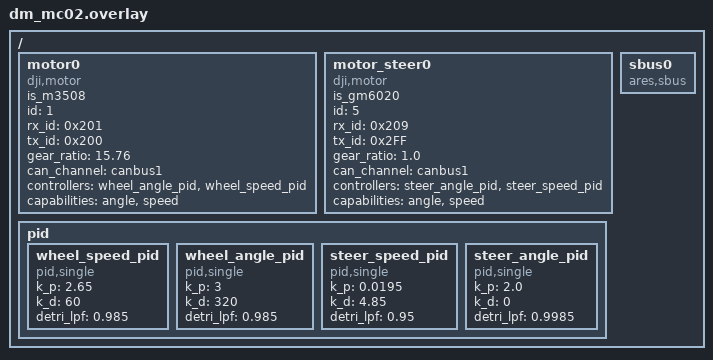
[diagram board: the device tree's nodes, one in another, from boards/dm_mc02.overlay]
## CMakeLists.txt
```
# SPDX-License-Identifier: Apache-2.0

cmake_minimum_required(VERSION 3.20.0)
set(CMAKE_CXX_STANDARD 11)
find_package(Zephyr REQUIRED HINTS $ENV{ZEPHYR_BASE})
project(motor)

FILE(GLOB app_sources src/*.c)

include_directories(${ZEPHYR_BASE}/include)
include_directories(${CMAKE_CURRENT_SOURCE_DIR}/include)
include_directories(${CMAKE_CURRENT_SOURCE_DIR}/dts)
target_sources(app PRIVATE ${app_sources})
target_include_directories(app PRIVATE ${ZEPHYR_BASE}/include)
target_include_directories(app PRIVATE ${CMAKE_CURRENT_SOURCE_DIR}/include)
target_include_directories(app PRIVATE ${CMAKE_CURRENT_SOURCE_DIR}/dts)
```

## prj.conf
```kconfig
# 启用线程分析器
CONFIG_THREAD_ANALYZER=y
CONFIG_THREAD_ANALYZER_USE_LOG=y
CONFIG_THREAD_ANALYZER_USE_PRINTK=n
CONFIG_THREAD_NAME=y
# CONFIG_THREAD_ANALYZER_AUTO=y
# CONFIG_THREAD_ANALYZER_AUTO_INTERVAL=5
CONFIG_THREAD_ANALYZER_LOG_LEVEL_INF=y
CONFIG_THREAD_ANALYZER_AUTO_SEPARATE_CORES=n

# 启用 Shell 支持
CONFIG_SHELL=n
CONFIG_SHELL_BACKENDS=n
CONFIG_SHELL_BACKEND_SERIAL=n

# 启用 UART 控制台
CONFIG_UART_CONSOLE=y

# 禁用 SEGGER RTT
CONFIG_USE_SEGGER_RTT=n

# 启用事件支持
CONFIG_EVENTS=y

# 启用控制台支持
CONFIG_CONSOLE=y

# 启用日志系统
CONFIG_LOG=y
CONFIG_LOG_MODE_IMMEDIATE=y
CONFIG_LOG_PRINTK=y
CONFIG_LOG_BACKEND_UART=y
# CONFIG_LOG_MODE_IMMEDIATE=y

# 启用串行支持
CONFIG_SERIAL=y

# 禁用优化
CONFIG_NO_OPTIMIZATIONS=n
CONFIG_COMPILER_OPT=""

# 启用驱动
CONFIG_MOTOR=y
CONFIG_MOTOR_DJI=y
CONFIG_MOTOR_LOG_LEVEL=4
CONFIG_CAN=y
CONFIG_MOTOR_INIT_PRIORITY=90

CONFIG_ARES=y

# use ASYNC uart API
CONFIG_SERIAL=y
CONFIG_UART_ASYNC_API=y
CONFIG_UART_INTERRUPT_DRIVEN=y

CONFIG_DMA=y
CONFIG_DMA_STM32=y  # STM32 DMA 驱动
CONFIG_UART_STM32=y # STM32 UART 驱动
# CONFIG_STM32_UART_DMA=y

# CONFIG_HAS_STM32CUBE=y
# CONFIG_USE_STM32_HAL_DMA=y
CONFIG_SPI=y
CONFIG_SPI_STM32=y

CONFIG_DEBUG=y

CONFIG_CMSIS_DSP=y
CONFIG_CMSIS_DSP_MATRIX=y
CONFIG_CMSIS_DSP_CONTROLLER=y
CONFIG_CMSIS_DSP_FASTMATH=y
```

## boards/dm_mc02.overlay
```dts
/ {
	motor0: motor0{
		compatible = "dji,motor";
		is_m3508;
		id = <1>;
		rx_id = <0x201>;
		tx_id = <0x200>;
		gear_ratio = "15.76";
		status = "okay";
		can_channel = <&canbus1>;
		controllers = <&wheel_angle_pid &wheel_speed_pid>;
		capabilities = "angle", "speed";
	};
	motor_steer0: motor_steer0{
		compatible = "dji,motor";
		is_gm6020;
		id = <5>;
		rx_id = <0x209>;
		tx_id = <0x2FF>;
		gear_ratio = "1.0";
		status = "okay";
		can_channel = <&canbus1>;
		controllers = <&steer_angle_pid &steer_speed_pid>;
		capabilities = "angle", "speed";
	};

	pid {
		wheel_speed_pid: wheel_speed_pid {
			#controller-cells = <0>;
			compatible = "pid,single";
			k_p = "2.65";
			k_d = "60";
			detri_lpf = "0.985";
		};

		wheel_angle_pid: wheel_angle_pid {
			#controller-cells = <0>;
			compatible = "pid,single";
			k_p = "3";
			k_d = "320";
			detri_lpf = "0.985";
		};

		steer_speed_pid: steer_speed_pid {
			#controller-cells = <0>;
			compatible = "pid,single";
			k_p = "0.0195";
			k_d = "4.85";
			detri_lpf = "0.95";
		};

		steer_angle_pid: steer_angle_pid {
			#controller-cells = <0>;
			compatible = "pid,single";
			k_p = "2.0";
			k_d = "0";
			detri_lpf = "0.9985";
		};
	};
	sbus0: sbus0 {
		compatible = "ares,sbus";
		status = "okay";
	};
};
```

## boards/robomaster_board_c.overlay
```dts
/ {
	motor0: motor0{
		compatible = "dji,motor";
		is_m3508;
		id = <1>;
		rx_id = <0x201>;
		tx_id = <0x200>;
		gear_ratio = "19.20";
		status = "okay";
		can_channel = <&canbus1>;
		controllers = <&speed_pid>;
		capabilities = "speed";
	};

	pid {
		speed_pid: speed_pid {
			#controller-cells = <0>;
			compatible = "pid,single";
			k_p = "1.8";
			k_i = "2.0";
			k_d = "2";
			detri_lpf = "0.985";
		};
	};
	sbus0: sbus0 {
		compatible = "ares,sbus";
		status = "okay";
	};
};
```

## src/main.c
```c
/*
 * Copyright (c) 2024 ttwards <12411711@mail.sustech.edu.cn>
 *
 * SPDX-License-Identifier: Apache-2.0
 */

#include <stddef.h>
#include <stdint.h>
#include <zephyr/device.h>
#include <zephyr/logging/log.h>
#include <zephyr/devicetree.h>
#include <zephyr/drivers/can.h>
#include <zephyr/debug/thread_analyzer.h>
#include <zephyr/kernel.h>
#include <zephyr/sys/printk.h>
#include <zephyr/drivers/motor.h>
#include <ares/board/init.h>

LOG_MODULE_REGISTER(main, LOG_LEVEL_DBG);

#define HIGH_BYTE(x)           ((x) >> 8)
#define LOW_BYTE(x)            ((x) & 0xFF)
#define COMBINE_HL8(HIGH, LOW) ((HIGH << 8) + LOW)

/* Devicetree */
#define CANBUS_NODE DT_CHOSEN(zephyr_canbus)
#define CAN1_NODE   DT_INST(0, vnd_canbus)
#define MOTOR1_NODE DT_INST(0, dji_motor)
#define MOTOR2_NODE DT_INST(1, dji_motor)

#define FEEDBACK_STACK_SIZE 1536

const struct device *can_dev = DEVICE_DT_GET(CANBUS_NODE);
const struct device *motor1 = DEVICE_DT_GET(MOTOR1_NODE);
const struct device *motor2 = DEVICE_DT_GET(MOTOR2_NODE);

/* CAN Feedback to console*/
void console_feedback(void *arg1, void *arg2, void *arg3)
{
	motor_status_t status;
	for (int i = 0; i < 10000; i++) {
		motor_get(motor1, &status);
		LOG_INF("Motor 1: Speed: %.2f, Set: %.2f", (double)status.rpm, (double)i);
		motor_get(motor2, &status);
		LOG_INF("Motor 2: Speed: %.2f, Set: %.2f", (double)status.rpm, (double)i);
		k_msleep(5);
	}
}
K_THREAD_DEFINE(feedback_thread, FEEDBACK_STACK_SIZE, console_feedback, NULL, NULL, NULL, 1, 0,
		100);

int main(void)
{
	k_msleep(1000);
	motor_control(motor1, ENABLE_MOTOR);
	motor_control(motor2, ENABLE_MOTOR);
	while (1) {
		k_msleep(1500);
	}
}
```

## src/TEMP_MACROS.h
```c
/* These are temporary vars.*/
/* They will be defined in device tree*/
/* However syscall is not done*/
#include <stdint.h>
#include <zephyr/kernel.h>

#define TOTAL_MOTORS 1


uint8_t motor_id[TOTAL_MOTORS] = {0x200};
```
